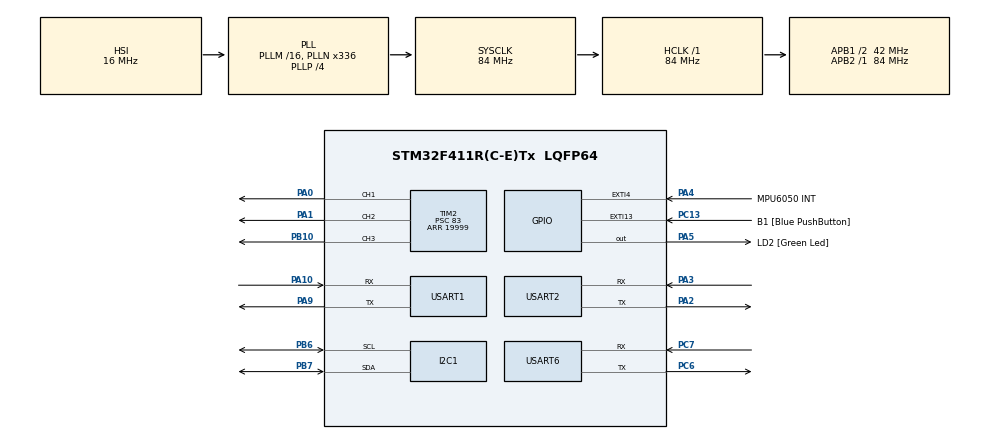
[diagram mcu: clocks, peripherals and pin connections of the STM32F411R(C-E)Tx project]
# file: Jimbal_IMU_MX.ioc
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ADC1.Channel-0\#ChannelRegularConversion=ADC_CHANNEL_VREFINT
ADC1.ContinuousConvMode=ENABLE
ADC1.DMAContinuousRequests=ENABLE
ADC1.NbrOfConversionFlag=1
ADC1.Rank-0\#ChannelRegularConversion=1
ADC1.SamplingTime-0\#ChannelRegularConversion=ADC_SAMPLETIME_84CYCLES
ADC1.ScanConvMode=ENABLE
ADC1.master=1
Dma.ADC1.0.Direction=DMA_PERIPH_TO_MEMORY
Dma.ADC1.0.FIFOMode=DMA_FIFOMODE_DISABLE
Dma.ADC1.0.Instance=DMA2_Stream0
Dma.ADC1.0.MemDataAlignment=DMA_MDATAALIGN_HALFWORD
Dma.ADC1.0.MemInc=DMA_MINC_ENABLE
Dma.ADC1.0.Mode=DMA_CIRCULAR
Dma.ADC1.0.PeriphDataAlignment=DMA_PDATAALIGN_HALFWORD
Dma.ADC1.0.PeriphInc=DMA_PINC_DISABLE
Dma.ADC1.0.Priority=DMA_PRIORITY_LOW
Dma.Request0=ADC1
FREERTOS.BinarySemaphores01=GyroReadySem,Dynamic,NULL,Available
FREERTOS.Tasks01=defaultTask,32,512,StartDefaultTask,As weak,NULL,Dynamic,NULL,NULL;myTaskLed,8,128,ledSystemTask,As weak,NULL,Dynamic,NULL,NULL;myTaskGyro,27,1024,gyroSystemTask,As weak,NULL,Dynamic,NULL,NULL;myTaskMonitor,29,512,monitorSystemTask,As weak,NULL,Dynamic,NULL,NULL;myTaskMag,27,512,magSystemTask,As weak,NULL,Dynamic,NULL,NULL;myTaskGimbal,27,512,gimbalSystemTask,As weak,NULL,Dynamic,NULL,NULL
FREERTOS.configCHECK_FOR_STACK_OVERFLOW=2
FREERTOS.configTOTAL_HEAP_SIZE=51200
FREERTOS.configUSE_NEWLIB_REENTRANT=1
Mcu.Family=STM32F4
Mcu.Name=STM32F411R(C-E)Tx
Mcu.Package=LQFP64
NVIC.DMA2_Stream0_IRQn=true\:5\:0\:false\:false\:true\:true\:false\:true\:true
NVIC.EXTI4_IRQn=true\:5\:0\:false\:false\:true\:true\:true\:true\:true
NVIC.PriorityGroup=NVIC_PRIORITYGROUP_4
NVIC.TIM1_UP_TIM10_IRQn=true\:15\:0\:false\:false\:true\:false\:false\:true\:true
NVIC.TimeBase=TIM1_UP_TIM10_IRQn
NVIC.TimeBaseIP=TIM10
NVIC.USART1_IRQn=true\:5\:0\:false\:false\:true\:true\:true\:true\:true
NVIC.USART2_IRQn=true\:5\:0\:true\:false\:true\:true\:true\:true\:true
NVIC.USART6_IRQn=true\:5\:0\:false\:false\:true\:true\:true\:true\:true
PA0-WKUP.Signal=S_TIM2_CH1_ETR
PA1.Signal=S_TIM2_CH2
PA10.Mode=Asynchronous
PA10.Signal=USART1_RX
PA13.GPIO_Label=TMS
PA13.Mode=Serial_Wire
PA13.Signal=SYS_JTMS-SWDIO
PA14.GPIO_Label=TCK
PA14.Mode=Serial_Wire
PA14.Signal=SYS_JTCK-SWCLK
PA2.GPIO_ModeDefaultPP=GPIO_MODE_AF_PP
PA2.GPIO_PuPd=GPIO_NOPULL
PA2.GPIO_Speed=GPIO_SPEED_FREQ_VERY_HIGH
PA2.Mode=Asynchronous
PA2.Signal=USART2_TX
PA3.GPIO_ModeDefaultPP=GPIO_MODE_AF_PP
PA3.GPIO_PuPd=GPIO_NOPULL
PA3.GPIO_Speed=GPIO_SPEED_FREQ_VERY_HIGH
PA3.Mode=Asynchronous
PA3.Signal=USART2_RX
PA4.GPIO_Label=MPU6050 INT
PA4.GPIO_PuPd=GPIO_PULLDOWN
PA4.Signal=GPXTI4
PA5.GPIO_Label=LD2 [Green Led]
PA5.Signal=GPIO_Output
PA9.Mode=Asynchronous
PA9.Signal=USART1_TX
PB10.Signal=S_TIM2_CH3
PB3.GPIO_Label=SWO
PB3.Signal=SYS_JTDO-SWO
PB6.Mode=I2C
PB6.Signal=I2C1_SCL
PB7.Mode=I2C
PB7.Signal=I2C1_SDA
PC13-ANTI_TAMP.GPIO_Label=B1 [Blue PushButton]
PC13-ANTI_TAMP.GPIO_ModeDefaultEXTI=GPIO_MODE_IT_FALLING
PC13-ANTI_TAMP.Signal=GPXTI13
PC14-OSC32_IN.Mode=LSE-External-Oscillator
PC14-OSC32_IN.Signal=RCC_OSC32_IN
PC15-OSC32_OUT.Mode=LSE-External-Oscillator
PC15-OSC32_OUT.Signal=RCC_OSC32_OUT
PC6.Mode=Asynchronous
PC6.Signal=USART6_TX
PC7.Mode=Asynchronous
PC7.Signal=USART6_RX
PH0\ -\ OSC_IN.Mode=HSE-External-Clock-Source
PH0\ -\ OSC_IN.Signal=RCC_OSC_IN
PH1\ -\ OSC_OUT.Mode=HSE-External-Clock-Source
PH1\ -\ OSC_OUT.Signal=RCC_OSC_OUT
ProjectManager.HeapSize=0x200
ProjectManager.StackSize=0x400
ProjectManager.TargetToolchain=CMake
RCC.48MHZClocksFreq_Value=84000000
RCC.AHBFreq_Value=84000000
RCC.APB1CLKDivider=RCC_HCLK_DIV2
RCC.APB1Freq_Value=42000000
RCC.APB1TimFreq_Value=84000000
RCC.APB2Freq_Value=84000000
RCC.APB2TimFreq_Value=84000000
RCC.CortexFreq_Value=84000000
RCC.FLatency-AdvancedSettings=FLASH_LATENCY_2
RCC.HCLKFreq_Value=84000000
RCC.HSE_VALUE=8000000
RCC.HSI_VALUE=16000000
RCC.PLLN=336
RCC.PLLP=RCC_PLLP_DIV4
RCC.SYSCLKFreq_VALUE=84000000
RCC.SYSCLKSource=RCC_SYSCLKSOURCE_PLLCLK
RCC.VCOOutputFreq_Value=336000000
SH.S_TIM2_CH1_ETR.0=TIM2_CH1,PWM Generation1 CH1
SH.S_TIM2_CH2.0=TIM2_CH2,PWM Generation2 CH2
SH.S_TIM2_CH3.0=TIM2_CH3,PWM Generation3 CH3
TIM2.Channel-PWM\ Generation1\ CH1=TIM_CHANNEL_1
TIM2.Channel-PWM\ Generation2\ CH2=TIM_CHANNEL_2
TIM2.Channel-PWM\ Generation3\ CH3=TIM_CHANNEL_3
TIM2.Period=19999
TIM2.Prescaler=83
TIM2.Pulse-PWM\ Generation1\ CH1=1500
TIM2.Pulse-PWM\ Generation2\ CH2=1500
USART1.VirtualMode=VM_ASYNC
USART2.VirtualMode=VM_ASYNC
USART6.VirtualMode=VM_ASYNC
VP_ADC1_TempSens_Input.Mode=IN-TempSens
VP_ADC1_Vref_Input.Mode=IN-Vrefint
VP_FREERTOS_VS_CMSIS_V2.Mode=CMSIS_V2
VP_SYS_VS_tim10.Mode=TIM10
VP_TIM2_VS_ClockSourceINT.Mode=Internal
board=NUCLEO-F411RE

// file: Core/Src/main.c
/* USER CODE BEGIN Header */
/**
  ******************************************************************************
  * @file           : main.c
  * @brief          : Main program body
  ******************************************************************************
  * @attention
  *
  * Copyright (c) 2026 STMicroelectronics.
  * All rights reserved.
  *
  * This software is licensed under terms that can be found in the LICENSE file
  * in the root directory of this software component.
  * If no LICENSE file comes with this software, it is provided AS-IS.
  *
  ******************************************************************************
  */
/* USER CODE END Header */
#include "main.h"
#include "cmsis_os.h"
#include "adc.h"
#include "dma.h"
#include "i2c.h"
#include "tim.h"
#include "usart.h"
#include "gpio.h"

void SystemClock_Config(void);
void MX_FREERTOS_Init(void);

int main(void)
{

  /* USER CODE BEGIN 1 */
  SCB->VTOR = 0x08008000; // Vector Table Offset Register 설정 (Sector 2 시작 주소)
  /* USER CODE END 1 */

  /* MCU Configuration--------------------------------------------------------*/

  /* Reset of all peripherals, Initializes the Flash interface and the Systick. */
  HAL_Init();

  /* Configure the system clock */
  SystemClock_Config();

  /* Initialize all configured peripherals */
  MX_GPIO_Init();
  MX_DMA_Init();
  MX_USART2_UART_Init();
  MX_I2C1_Init();
  MX_ADC1_Init();
  MX_TIM2_Init();
  MX_USART1_UART_Init();
  MX_USART6_UART_Init();

  /* Init scheduler */
  osKernelInitialize();  /* Call init function for freertos objects (in cmsis_os2.c) */
  MX_FREERTOS_Init();

  /* Start scheduler */
  osKernelStart();

  /* We should never get here as control is now taken by the scheduler */

  /* Infinite loop */
  while (1)
  {

  }
}

void SystemClock_Config(void)
{
  RCC_OscInitTypeDef RCC_OscInitStruct = {0};
  RCC_ClkInitTypeDef RCC_ClkInitStruct = {0};

  /** Configure the main internal regulator output voltage
  */
  __HAL_RCC_PWR_CLK_ENABLE();
  __HAL_PWR_VOLTAGESCALING_CONFIG(PWR_REGULATOR_VOLTAGE_SCALE1);

  /** Initializes the RCC Oscillators according to the specified parameters
  * in the RCC_OscInitTypeDef structure.
  */
  RCC_OscInitStruct.OscillatorType = RCC_OSCILLATORTYPE_HSI;
  RCC_OscInitStruct.HSIState = RCC_HSI_ON;
  RCC_OscInitStruct.HSICalibrationValue = RCC_HSICALIBRATION_DEFAULT;
  RCC_OscInitStruct.PLL.PLLState = RCC_PLL_ON;
  RCC_OscInitStruct.PLL.PLLSource = RCC_PLLSOURCE_HSI;
  RCC_OscInitStruct.PLL.PLLM = 16;
  RCC_OscInitStruct.PLL.PLLN = 336;
  RCC_OscInitStruct.PLL.PLLP = RCC_PLLP_DIV4;
  RCC_OscInitStruct.PLL.PLLQ = 4;
  if (HAL_RCC_OscConfig(&RCC_OscInitStruct) != HAL_OK)
  {
    Error_Handler();
  }

  /** Initializes the CPU, AHB and APB buses clocks
  */
  RCC_ClkInitStruct.ClockType = RCC_CLOCKTYPE_HCLK|RCC_CLOCKTYPE_SYSCLK
                              |RCC_CLOCKTYPE_PCLK1|RCC_CLOCKTYPE_PCLK2;
  RCC_ClkInitStruct.SYSCLKSource = RCC_SYSCLKSOURCE_PLLCLK;
  RCC_ClkInitStruct.AHBCLKDivider = RCC_SYSCLK_DIV1;
  RCC_ClkInitStruct.APB1CLKDivider = RCC_HCLK_DIV2;
  RCC_ClkInitStruct.APB2CLKDivider = RCC_HCLK_DIV1;

  if (HAL_RCC_ClockConfig(&RCC_ClkInitStruct, FLASH_LATENCY_2) != HAL_OK)
  {
    Error_Handler();
  }
}

/* USER CODE BEGIN 4 */
extern osSemaphoreId_t GyroReadySemHandle;

void HAL_GPIO_EXTI_Callback(uint16_t GPIO_Pin)
{
    // [수정 전] if(GPIO_Pin == GPIO_PIN_0)
    // [수정 후] PA4 핀에서 발생한 인터럽트인지 확인합니다.
    if(GPIO_Pin == GPIO_PIN_4)
    {
        if(GyroReadySemHandle != NULL) {
            osSemaphoreRelease(GyroReadySemHandle);
        }
    }

    // (만약 기존 파란색 버튼 PC13 코드가 있다면 아래에 그대로 유지하시면 됩니다.)
    // else if (GPIO_Pin == GPIO_PIN_13) { ... }
}
/* USER CODE END 4 */

void HAL_TIM_PeriodElapsedCallback(TIM_HandleTypeDef *htim)
{
  if (htim->Instance == TIM10)
  {
    HAL_IncTick();
  }
}

void Error_Handler(void)
{
  __disable_irq();
  while (1)
  {
  }
}

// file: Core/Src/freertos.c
/* USER CODE BEGIN Header */
/**
  ******************************************************************************
  * File Name          : freertos.c
  * Description        : Code for freertos applications
  ******************************************************************************
  * @attention
  *
  * Copyright (c) 2026 STMicroelectronics.
  * All rights reserved.
  *
  * This software is licensed under terms that can be found in the LICENSE file
  * in the root directory of this software component.
  * If no LICENSE file comes with this software, it is provided AS-IS.
  *
  ******************************************************************************
  */
/* USER CODE END Header */

#include "FreeRTOS.h"
#include "task.h"
#include "main.h"
#include "cmsis_os.h"

/* Definitions for defaultTask */
osThreadId_t defaultTaskHandle;
const osThreadAttr_t defaultTask_attributes = {
  .name = "defaultTask",
  .stack_size = 512 * 4,
  .priority = (osPriority_t) osPriorityAboveNormal,
};
/* Definitions for myTaskLed */
osThreadId_t myTaskLedHandle;
const osThreadAttr_t myTaskLed_attributes = {
  .name = "myTaskLed",
  .stack_size = 128 * 4,
  .priority = (osPriority_t) osPriorityLow,
};
/* Definitions for myTaskGyro */
osThreadId_t myTaskGyroHandle;
const osThreadAttr_t myTaskGyro_attributes = {
  .name = "myTaskGyro",
  .stack_size = 1024 * 4,
  .priority = (osPriority_t) osPriorityNormal3,
};
/* Definitions for myTaskMonitor */
osThreadId_t myTaskMonitorHandle;
const osThreadAttr_t myTaskMonitor_attributes = {
  .name = "myTaskMonitor",
  .stack_size = 512 * 4,
  .priority = (osPriority_t) osPriorityNormal5,
};
/* Definitions for myTaskMag */
osThreadId_t myTaskMagHandle;
const osThreadAttr_t myTaskMag_attributes = {
  .name = "myTaskMag",
  .stack_size = 512 * 4,
  .priority = (osPriority_t) osPriorityNormal3,
};
/* Definitions for myTaskGimbal */
osThreadId_t myTaskGimbalHandle;
const osThreadAttr_t myTaskGimbal_attributes = {
  .name = "myTaskGimbal",
  .stack_size = 512 * 4,
  .priority = (osPriority_t) osPriorityNormal3,
};
/* Definitions for GyroReadySem */
osSemaphoreId_t GyroReadySemHandle;
const osSemaphoreAttr_t GyroReadySem_attributes = {
  .name = "GyroReadySem"
};

void StartDefaultTask(void *argument);
void ledSystemTask(void *argument);
void gyroSystemTask(void *argument);
void monitorSystemTask(void *argument);
void magSystemTask(void *argument);
void gimbalSystemTask(void *argument);

void MX_FREERTOS_Init(void); /* (MISRA C 2004 rule 8.1) */

/* Hook prototypes */
void vApplicationStackOverflowHook(xTaskHandle xTask, signed char *pcTaskName);

/* USER CODE BEGIN 4 */
__weak void vApplicationStackOverflowHook(xTaskHandle xTask, signed char *pcTaskName)
{
   /* Run time stack overflow checking is performed if
   configCHECK_FOR_STACK_OVERFLOW is defined to 1 or 2. This hook function is
   called if a stack overflow is detected. */
}
/* USER CODE END 4 */

void MX_FREERTOS_Init(void) {

  /* Create the semaphores(s) */
  /* creation of GyroReadySem */
  GyroReadySemHandle = osSemaphoreNew(1, 1, &GyroReadySem_attributes);

  /* Create the thread(s) */
  /* creation of defaultTask */
  defaultTaskHandle = osThreadNew(StartDefaultTask, NULL, &defaultTask_attributes);

  /* creation of myTaskLed */
  myTaskLedHandle = osThreadNew(ledSystemTask, NULL, &myTaskLed_attributes);

  /* creation of myTaskGyro */
  myTaskGyroHandle = osThreadNew(gyroSystemTask, NULL, &myTaskGyro_attributes);

  /* creation of myTaskMonitor */
  myTaskMonitorHandle = osThreadNew(monitorSystemTask, NULL, &myTaskMonitor_attributes);

  /* creation of myTaskMag */
  myTaskMagHandle = osThreadNew(magSystemTask, NULL, &myTaskMag_attributes);

  /* creation of myTaskGimbal */
  myTaskGimbalHandle = osThreadNew(gimbalSystemTask, NULL, &myTaskGimbal_attributes);

}

__weak void StartDefaultTask(void *argument)
{
  for(;;)
  {
    osDelay(1);
  }
}

__weak void ledSystemTask(void *argument)
{
  for(;;)
  {
    osDelay(1);
  }
}

__weak void gyroSystemTask(void *argument)
{
  for(;;)
  {
    osDelay(1);
  }
}

__weak void monitorSystemTask(void *argument)
{
  for(;;)
  {
    osDelay(1);
  }
}

__weak void magSystemTask(void *argument)
{
  for(;;)
  {
    osDelay(1);
  }
}

__weak void gimbalSystemTask(void *argument)
{
  for(;;)
  {
    osDelay(1);
  }
}
